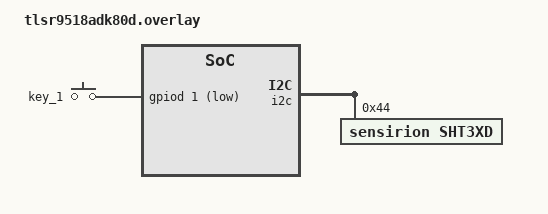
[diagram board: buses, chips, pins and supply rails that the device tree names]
/*
 * Copyright (c) 2023 Telink Semiconductor
 *
 * SPDX-License-Identifier: Apache-2.0
 */

/ {
	keys {
		/delete-node/ button_1;
		compatible = "gpio-keys";
		key_1: button_1 {
			gpios = <&gpiod 1 (GPIO_PULL_UP | GPIO_ACTIVE_LOW)>;
		};
	};
};

&pinctrl {
	/* Define I2C pins: SCL(PE0), SDA(PC2) */
	i2c_scl_pe0_default: i2c_scl_pe0_default {
		pinmux = <B9x_PINMUX_SET(B9x_PORT_E, B9x_PIN_0, B91_FUNC_A)>;
	};
	i2c_sda_pc2_default: i2c_sda_pc2_default {
		pinmux = <B9x_PINMUX_SET(B9x_PORT_C, B9x_PIN_2, B91_FUNC_A)>;
	};
};

&i2c {
	pinctrl-0 = <&i2c_scl_pe0_default &i2c_sda_pc2_default>;

	sht3xd@44 {
		compatible = "sensirion,sht3xd";
		reg = <0x44>;
	};
};
